# apollo4p register map
Vendor: Ambiq Micro; Series: Apollo; File version: 1.0
CPU: CM4 r1p0, little endian, MPU, FPU, I-cache, D-cache, VTOR, ITCM, DTCM, 3 interrupt priority bits, 0 interrupts
Registers are 32-bit, read-write, reset 0x0 unless marked. A register's access mark holds for its fields unless they carry their own. Offsets are from the block's base; [hi:lo] are bit positions; {n}, {i} and the like mark numbered series; 'fields as' and 'values as' point back to an identical list.

## GPIO (part 4 of 5) — General Purpose IO
Base 0x40010000
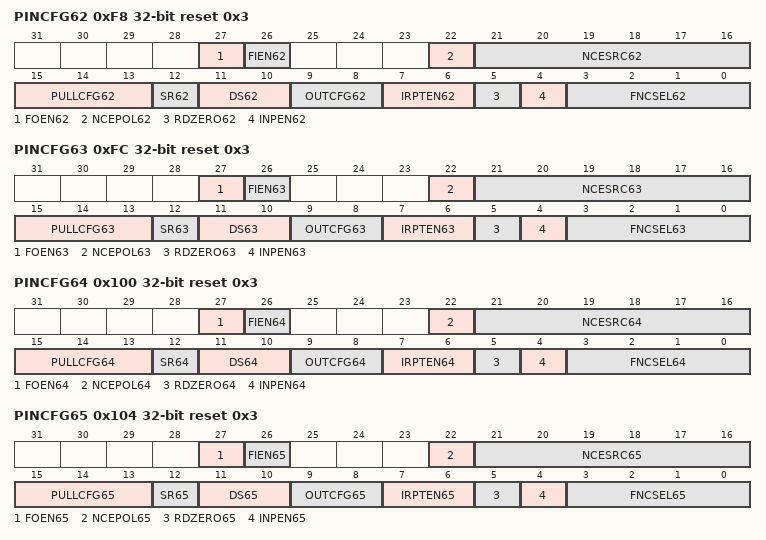
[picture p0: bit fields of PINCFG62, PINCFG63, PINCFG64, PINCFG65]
0xF8 PINCFG62 reset 0x3 — Controls the operation of GPIO pin 62.
  [27] FOEN62 — Force output enable active regardless of function selected. Otherwise the selected function will enable the output only when needed
  [26] FIEN62 — Force input enable active regardless of function selected. Otherwise the selected function will enable the input only when needed
  [22] NCEPOL62 — Polarity select for NCE for GPIO 62
    0=LOW (Polarity is active low); 1=HIGH (Polarity is active high)
  [21:16] NCESRC62 — IOMSTR/MSPI N Chip Select 62, DISP control signals DE, CSX, and CS. Polarity is determined by CE_POLARITY field
    {v}=IOM0CE{v} (IOM 0 NCE {v} module) (v=0..3); {v}=IOM1CE{v-4} (IOM 1 NCE {v-4} module) (v=4..7); {v}=IOM2CE{v-8} (IOM 2 NCE {v-8} module) (v=8..11); {v}=IOM3CE{v-12} (IOM 3 NCE {v-12} module) (v=12..15); {v}=IOM4CE{v-16} (IOM 4 NCE {v-16} module) (v=16..19); {v}=IOM5CE{v-20} (IOM 5 NCE {v-20} module) (v=20..23); {v}=IOM6CE{v-24} (IOM 6 NCE {v-24} module) (v=24..27); {v}=IOM7CE{v-28} (IOM 7 NCE {v-28} module) (v=28..31); 32=MSPI0CEN0 (MSPI 0 NCE 0 module); 33=MSPI0CEN1 (MSPI 0 NCE 1 module); 34=MSPI1CEN0 (MSPI 1 NCE 0 module); 35=MSPI1CEN1 (MSPI 1 NCE 1 module); 36=MSPI2CEN0 (MSPI 2 NCE 0 module); 37=MSPI2CEN1 (MSPI 2 NCE 1 module); 38=DC_DPI_DE (DC DPI DE module); 39=DISP_CONT_CSX (DISP CONT CSX module); 40=DC_SPI_CS_N (DC SPI CS_N module); 41=DC_QSPI_CS_N (DC QSPI CS_N module); 42=DC_RESX (DC module RESX)
  [15:13] PULLCFG62 — Pullup/Pulldown configuration for GPIO 62
    0=DIS (No pullup or pulldown selected); 1=PD50K (50K Pulldown selected); 2=PU15K (1.5K Pullup selected); 3=PU6K (6K Pullup selected); 4=PU12K (12K Pullup selected); 5=PU24K (24K Pullup selected); 6=PU50K (50K Pullup selected); 7=PU100K (100K Pullup selected)
  [12] SR62 — Configure the slew rate
  [11:10] DS62 — Drive strength selection for GPIO 62
    0=0P1X (0.1x output driver selected); 1=0P5X (0.5x output driver selected); 2=0P75X (0.75x output driver selected); 3=1P0X (1.0x output driver selected)
  [9:8] OUTCFG62 — Pin IO mode selection for GPIO pin 62
    0=DIS (Output Disabled); 1=PUSHPULL (Output configured in push pull mode. Will drive 0 and 1 values on pin.); 2=OD (Output configured in open drain mode. Will only drive pin low, tristate otherwise.); 3=TS (Output configured in Tristate-able push pull mode. Will drive 0, 1 of HiZ on pin.)
  [7:6] IRPTEN62 — Interrupt enable for GPIO 62
    0=DIS (Interrupts are disabled for this GPIO); 1=INTFALL (Interrupts are enabled for falling edge transition on this GPIO); 2=INTRISE (Interrupts are enabled for rising edge transitions on this GPIO); 3=INTANY (Interrupts are enabled for any edge transition on this GPIO)
  [5] RDZERO62 — Return 0 for read data on GPIO 62
  [4] INPEN62 — Input enable for GPIO 62
  [3:0] FNCSEL62 — Function select for GPIO pin 62
    0=M6SDAWIR3 (Serial I2C Master Data I/O (I2C Mode) Serial SPI Master Data I/O (SPI 3 wire mode) (IOM 6)); 1=M6MOSI (Serial SPI Master MOSI output (IOM 6)); 2=I2S1_DATA (Bidirectional I2S Data. Operates in output mode in master mode and input mode for slave mode. (I2S Master/Slave 2)); 3=GPIO (General purpose I/O); 4=UART0RX (UART receive input (UART 0)); 5=UART1RX (UART receive input (UART 1)); 6=CT62 (Timer/Counter input or output; Selection of direction is done via CTIMER register settings.); 7=NCE62 (IOMSTR/MSPI N Chip Select. Polarity is determined by CE_POLARITY field); 8=OBSBUS14 (Observation bus bit 14); 9=I2S1_SDOUT (I2S Data output (I2S Master/Slave 2)); 10=I3CM0_SDA (Serial I3C Master Data I/O (IOM 0)); 11=FPIO (Fast PIO)
0xFC PINCFG63 reset 0x3 — Controls the operation of GPIO pin 63.
  [27] FOEN63 — Force output enable active regardless of function selected. Otherwise the selected function will enable the output only when needed
  [26] FIEN63 — Force input enable active regardless of function selected. Otherwise the selected function will enable the input only when needed
  [22] NCEPOL63 — Polarity select for NCE for GPIO 63
    values as PINCFG62.NCEPOL62
  [21:16] NCESRC63 — IOMSTR/MSPI N Chip Select 63, DISP control signals DE, CSX, and CS. Polarity is determined by CE_POLARITY field
    values as PINCFG62.NCESRC62
  [15:13] PULLCFG63 — Pullup/Pulldown configuration for GPIO 63
    values as PINCFG62.PULLCFG62
  [12] SR63 — Configure the slew rate
  [11:10] DS63 — Drive strength selection for GPIO 63
    values as PINCFG62.DS62
  [9:8] OUTCFG63 — Pin IO mode selection for GPIO pin 63
    values as PINCFG62.OUTCFG62
  [7:6] IRPTEN63 — Interrupt enable for GPIO 63
    values as PINCFG62.IRPTEN62
  [5] RDZERO63 — Return 0 for read data on GPIO 63
  [4] INPEN63 — Input enable for GPIO 63
  [3:0] FNCSEL63 — Function select for GPIO pin 63
    0=M6MISO (Serial SPI MASTER MISO input (IOM 6)); 1=CLKOUT (Oscillator output clock); 2=I2S1_WS (Bidirectional I2S L/R clock. Operates in output mode in master mode and input mode for slave mode. (I2S Master/Slave 2)); 3=GPIO (General purpose I/O); 4=UART2RX (UART receive input (UART 2)); 5=UART3RX (UART receive input (UART 3)); 6=CT63 (Timer/Counter input or output; Selection of direction is done via CTIMER register settings.); 7=NCE63 (IOMSTR/MSPI N Chip Select. Polarity is determined by CE_POLARITY field); 8=OBSBUS15 (Observation bus bit 15); 9=DISP_TE (Display TE input); 11=FPIO (Fast PIO)
0x100 PINCFG64 reset 0x3 — Controls the operation of GPIO pin 64.
  [27] FOEN64 — Force output enable active regardless of function selected. Otherwise the selected function will enable the output only when needed
  [26] FIEN64 — Force input enable active regardless of function selected. Otherwise the selected function will enable the input only when needed
  [22] NCEPOL64 — Polarity select for NCE for GPIO 64
    values as PINCFG62.NCEPOL62
  [21:16] NCESRC64 — IOMSTR/MSPI N Chip Select 64, DISP control signals DE, CSX, and CS. Polarity is determined by CE_POLARITY field
    values as PINCFG62.NCESRC62
  [15:13] PULLCFG64 — Pullup/Pulldown configuration for GPIO 64
    values as PINCFG62.PULLCFG62
  [12] SR64 — Configure the slew rate
  [11:10] DS64 — Drive strength selection for GPIO 64
    values as PINCFG62.DS62
  [9:8] OUTCFG64 — Pin IO mode selection for GPIO pin 64
    values as PINCFG62.OUTCFG62
  [7:6] IRPTEN64 — Interrupt enable for GPIO 64
    values as PINCFG62.IRPTEN62
  [5] RDZERO64 — Return 0 for read data on GPIO 64
  [4] INPEN64 — Input enable for GPIO 64
  [3:0] FNCSEL64 — Function select for GPIO pin 64
    0=MSPI0_0 (MSPI Master 0 Interface Signal); 1=32KHzXT (32kHZ from analog); 2=SWO (Serial Wire Output); 3=GPIO (General purpose I/O); 4=UART0RTS (UART Request to Send (RTS) (UART 0)); 5=DISP_D0 (Display Data 0); 6=CT64 (Timer/Counter input or output; Selection of direction is done via CTIMER register settings.); 7=NCE64 (IOMSTR/MSPI N Chip Select. Polarity is determined by CE_POLARITY field); 8=OBSBUS0 (Observation bus bit 0); 9=I2S1_SDIN (I2S Data input (I2S Master/Slave 2)); 11=FPIO (Fast PIO)
0x104 PINCFG65 reset 0x3 — Controls the operation of GPIO pin 65.
  [27] FOEN65 — Force output enable active regardless of function selected. Otherwise the selected function will enable the output only when needed
  [26] FIEN65 — Force input enable active regardless of function selected. Otherwise the selected function will enable the input only when needed
  [22] NCEPOL65 — Polarity select for NCE for GPIO 65
    values as PINCFG62.NCEPOL62
  [21:16] NCESRC65 — IOMSTR/MSPI N Chip Select 65, DISP control signals DE, CSX, and CS. Polarity is determined by CE_POLARITY field
    values as PINCFG62.NCESRC62
  [15:13] PULLCFG65 — Pullup/Pulldown configuration for GPIO 65
    values as PINCFG62.PULLCFG62
  [12] SR65 — Configure the slew rate
  [11:10] DS65 — Drive strength selection for GPIO 65
    values as PINCFG62.DS62
  [9:8] OUTCFG65 — Pin IO mode selection for GPIO pin 65
    values as PINCFG62.OUTCFG62
  [7:6] IRPTEN65 — Interrupt enable for GPIO 65
    values as PINCFG62.IRPTEN62
  [5] RDZERO65 — Return 0 for read data on GPIO 65
  [4] INPEN65 — Input enable for GPIO 65
  [3:0] FNCSEL65 — Function select for GPIO pin 65
    0=MSPI0_1 (MSPI Master 0 Interface Signal); 1=32KHzXT (32kHZ from analog); 2=SWO (Serial Wire Output); 3=GPIO (General purpose I/O); 4=UART0CTS (UART Clear to Send (CTS) (UART 0)); 5=DISP_D1 (Display Data 1); 6=CT65 (Timer/Counter input or output; Selection of direction is done via CTIMER register settings.); 7=NCE65 (IOMSTR/MSPI N Chip Select. Polarity is determined by CE_POLARITY field); 8=OBSBUS1 (Observation bus bit 1); 11=FPIO (Fast PIO)
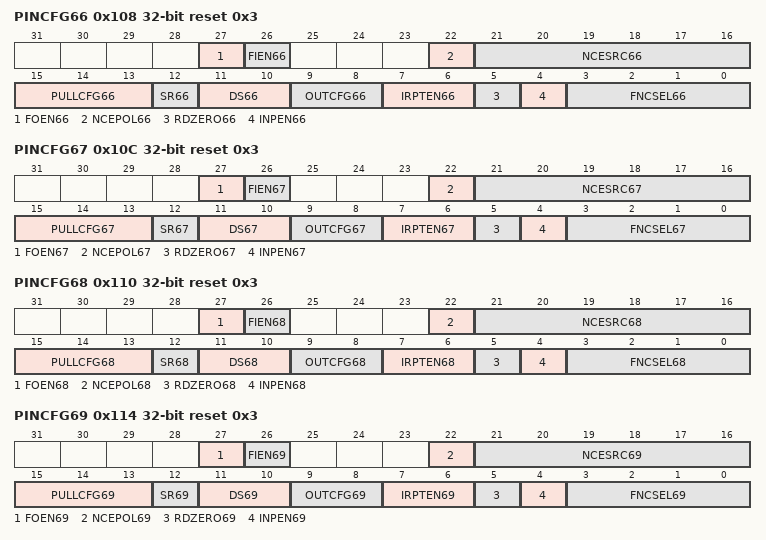
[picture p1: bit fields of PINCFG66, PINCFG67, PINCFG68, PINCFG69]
0x108 PINCFG66 reset 0x3 — Controls the operation of GPIO pin 66.
  [27] FOEN66 — Force output enable active regardless of function selected. Otherwise the selected function will enable the output only when needed
  [26] FIEN66 — Force input enable active regardless of function selected. Otherwise the selected function will enable the input only when needed
  [22] NCEPOL66 — Polarity select for NCE for GPIO 66
    values as PINCFG62.NCEPOL62
  [21:16] NCESRC66 — IOMSTR/MSPI N Chip Select 66, DISP control signals DE, CSX, and CS. Polarity is determined by CE_POLARITY field
    values as PINCFG62.NCESRC62
  [15:13] PULLCFG66 — Pullup/Pulldown configuration for GPIO 66
    values as PINCFG62.PULLCFG62
  [12] SR66 — Configure the slew rate
  [11:10] DS66 — Drive strength selection for GPIO 66
    values as PINCFG62.DS62
  [9:8] OUTCFG66 — Pin IO mode selection for GPIO pin 66
    values as PINCFG62.OUTCFG62
  [7:6] IRPTEN66 — Interrupt enable for GPIO 66
    values as PINCFG62.IRPTEN62
  [5] RDZERO66 — Return 0 for read data on GPIO 66
  [4] INPEN66 — Input enable for GPIO 66
  [3:0] FNCSEL66 — Function select for GPIO pin 66
    0=MSPI0_2 (MSPI Master 0 Interface Signal); 1=CLKOUT (Oscillator output clock); 2=SWO (Serial Wire Output); 3=GPIO (General purpose I/O); 4=UART0TX (UART transmit output (UART 0)); 5=DISP_D2 (Display Data 2); 6=CT66 (Timer/Counter input or output; Selection of direction is done via CTIMER register settings.); 7=NCE66 (IOMSTR/MSPI N Chip Select. Polarity is determined by CE_POLARITY field); 8=OBSBUS2 (Observation bus bit 2); 11=FPIO (Fast PIO)
0x10C PINCFG67 reset 0x3 — Controls the operation of GPIO pin 67.
  [27] FOEN67 — Force output enable active regardless of function selected. Otherwise the selected function will enable the output only when needed
  [26] FIEN67 — Force input enable active regardless of function selected. Otherwise the selected function will enable the input only when needed
  [22] NCEPOL67 — Polarity select for NCE for GPIO 67
    values as PINCFG62.NCEPOL62
  [21:16] NCESRC67 — IOMSTR/MSPI N Chip Select 67, DISP control signals DE, CSX, and CS. Polarity is determined by CE_POLARITY field
    values as PINCFG62.NCESRC62
  [15:13] PULLCFG67 — Pullup/Pulldown configuration for GPIO 67
    values as PINCFG62.PULLCFG62
  [12] SR67 — Configure the slew rate
  [11:10] DS67 — Drive strength selection for GPIO 67
    values as PINCFG62.DS62
  [9:8] OUTCFG67 — Pin IO mode selection for GPIO pin 67
    values as PINCFG62.OUTCFG62
  [7:6] IRPTEN67 — Interrupt enable for GPIO 67
    values as PINCFG62.IRPTEN62
  [5] RDZERO67 — Return 0 for read data on GPIO 67
  [4] INPEN67 — Input enable for GPIO 67
  [3:0] FNCSEL67 — Function select for GPIO pin 67
    0=MSPI0_3 (MSPI Master 0 Interface Signal); 1=CLKOUT (Oscillator output clock); 2=SWO (Serial Wire Output); 3=GPIO (General purpose I/O); 4=UART2TX (UART transmit output (UART 2)); 5=DISP_D3 (Display Data 3); 6=CT67 (Timer/Counter input or output; Selection of direction is done via CTIMER register settings.); 7=NCE67 (IOMSTR/MSPI N Chip Select. Polarity is determined by CE_POLARITY field); 8=OBSBUS3 (Observation bus bit 3); 11=FPIO (Fast PIO)
0x110 PINCFG68 reset 0x3 — Controls the operation of GPIO pin 68.
  [27] FOEN68 — Force output enable active regardless of function selected. Otherwise the selected function will enable the output only when needed
  [26] FIEN68 — Force input enable active regardless of function selected. Otherwise the selected function will enable the input only when needed
  [22] NCEPOL68 — Polarity select for NCE for GPIO 68
    values as PINCFG62.NCEPOL62
  [21:16] NCESRC68 — IOMSTR/MSPI N Chip Select 68, DISP control signals DE, CSX, and CS. Polarity is determined by CE_POLARITY field
    values as PINCFG62.NCESRC62
  [15:13] PULLCFG68 — Pullup/Pulldown configuration for GPIO 68
    values as PINCFG62.PULLCFG62
  [12] SR68 — Configure the slew rate
  [11:10] DS68 — Drive strength selection for GPIO 68
    values as PINCFG62.DS62
  [9:8] OUTCFG68 — Pin IO mode selection for GPIO pin 68
    values as PINCFG62.OUTCFG62
  [7:6] IRPTEN68 — Interrupt enable for GPIO 68
    values as PINCFG62.IRPTEN62
  [5] RDZERO68 — Return 0 for read data on GPIO 68
  [4] INPEN68 — Input enable for GPIO 68
  [3:0] FNCSEL68 — Function select for GPIO pin 68
    0=MSPI0_4 (MSPI Master 0 Interface Signal); 1=SWO (Serial Wire Output); 3=GPIO (General purpose I/O); 4=UART0RX (UART receive input (UART 0)); 5=DISP_D4 (Display Data 4); 6=CT68 (Timer/Counter input or output; Selection of direction is done via CTIMER register settings.); 7=NCE68 (IOMSTR/MSPI N Chip Select. Polarity is determined by CE_POLARITY field); 8=OBSBUS4 (Observation bus bit 4); 11=FPIO (Fast PIO)
0x114 PINCFG69 reset 0x3 — Controls the operation of GPIO pin 69.
  [27] FOEN69 — Force output enable active regardless of function selected. Otherwise the selected function will enable the output only when needed
  [26] FIEN69 — Force input enable active regardless of function selected. Otherwise the selected function will enable the input only when needed
  [22] NCEPOL69 — Polarity select for NCE for GPIO 69
    values as PINCFG62.NCEPOL62
  [21:16] NCESRC69 — IOMSTR/MSPI N Chip Select 69, DISP control signals DE, CSX, and CS. Polarity is determined by CE_POLARITY field
    values as PINCFG62.NCESRC62
  [15:13] PULLCFG69 — Pullup/Pulldown configuration for GPIO 69
    values as PINCFG62.PULLCFG62
  [12] SR69 — Configure the slew rate
  [11:10] DS69 — Drive strength selection for GPIO 69
    values as PINCFG62.DS62
  [9:8] OUTCFG69 — Pin IO mode selection for GPIO pin 69
    values as PINCFG62.OUTCFG62
  [7:6] IRPTEN69 — Interrupt enable for GPIO 69
    values as PINCFG62.IRPTEN62
  [5] RDZERO69 — Return 0 for read data on GPIO 69
  [4] INPEN69 — Input enable for GPIO 69
  [3:0] FNCSEL69 — Function select for GPIO pin 69
    0=MSPI0_5 (MSPI Master 0 Interface Signal); 1=32KHzXT (32kHZ from analog); 2=SWO (Serial Wire Output); 3=GPIO (General purpose I/O); 4=UART2RX (UART receive input (UART 2)); 5=DISP_D5 (Display Data 5); 6=CT69 (Timer/Counter input or output; Selection of direction is done via CTIMER register settings.); 7=NCE69 (IOMSTR/MSPI N Chip Select. Polarity is determined by CE_POLARITY field); 8=OBSBUS5 (Observation bus bit 5); 11=FPIO (Fast PIO)
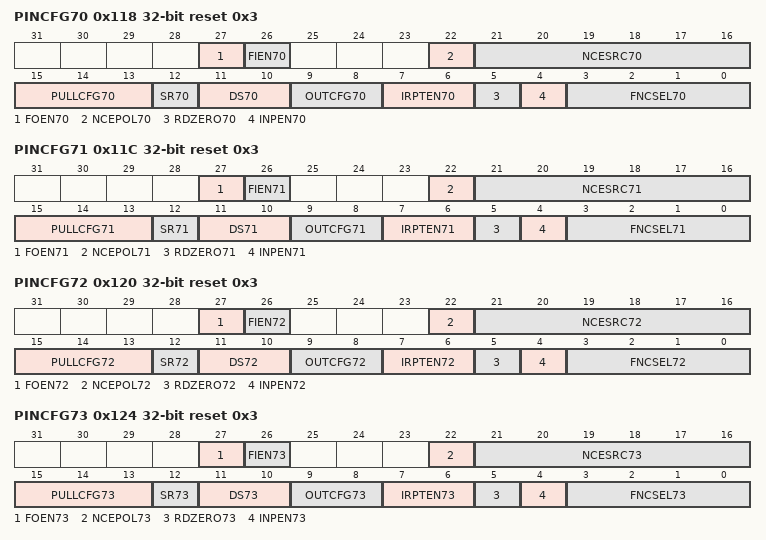
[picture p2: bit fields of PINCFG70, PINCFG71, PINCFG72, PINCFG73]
0x118 PINCFG70 reset 0x3 — Controls the operation of GPIO pin 70.
  [27] FOEN70 — Force output enable active regardless of function selected. Otherwise the selected function will enable the output only when needed
  [26] FIEN70 — Force input enable active regardless of function selected. Otherwise the selected function will enable the input only when needed
  [22] NCEPOL70 — Polarity select for NCE for GPIO 70
    values as PINCFG62.NCEPOL62
  [21:16] NCESRC70 — IOMSTR/MSPI N Chip Select 70, DISP control signals DE, CSX, and CS. Polarity is determined by CE_POLARITY field
    values as PINCFG62.NCESRC62
  [15:13] PULLCFG70 — Pullup/Pulldown configuration for GPIO 70
    values as PINCFG62.PULLCFG62
  [12] SR70 — Configure the slew rate
  [11:10] DS70 — Drive strength selection for GPIO 70
    values as PINCFG62.DS62
  [9:8] OUTCFG70 — Pin IO mode selection for GPIO pin 70
    values as PINCFG62.OUTCFG62
  [7:6] IRPTEN70 — Interrupt enable for GPIO 70
    values as PINCFG62.IRPTEN62
  [5] RDZERO70 — Return 0 for read data on GPIO 70
  [4] INPEN70 — Input enable for GPIO 70
  [3:0] FNCSEL70 — Function select for GPIO pin 70
    0=MSPI0_6 (MSPI Master 0 Interface Signal); 1=32KHzXT (32kHZ from analog); 2=SWTRACE0 (Serial Wire Debug Trace Output 0); 3=GPIO (General purpose I/O); 4=UART0RTS (UART Request to Send (RTS) (UART 0)); 5=DISP_D6 (Display Data 6); 6=CT70 (Timer/Counter input or output; Selection of direction is done via CTIMER register settings.); 7=NCE70 (IOMSTR/MSPI N Chip Select. Polarity is determined by CE_POLARITY field); 8=OBSBUS6 (Observation bus bit 6); 11=FPIO (Fast PIO)
0x11C PINCFG71 reset 0x3 — Controls the operation of GPIO pin 71.
  [27] FOEN71 — Force output enable active regardless of function selected. Otherwise the selected function will enable the output only when needed
  [26] FIEN71 — Force input enable active regardless of function selected. Otherwise the selected function will enable the input only when needed
  [22] NCEPOL71 — Polarity select for NCE for GPIO 71
    values as PINCFG62.NCEPOL62
  [21:16] NCESRC71 — IOMSTR/MSPI N Chip Select 71, DISP control signals DE, CSX, and CS. Polarity is determined by CE_POLARITY field
    values as PINCFG62.NCESRC62
  [15:13] PULLCFG71 — Pullup/Pulldown configuration for GPIO 71
    values as PINCFG62.PULLCFG62
  [12] SR71 — Configure the slew rate
  [11:10] DS71 — Drive strength selection for GPIO 71
    values as PINCFG62.DS62
  [9:8] OUTCFG71 — Pin IO mode selection for GPIO pin 71
    values as PINCFG62.OUTCFG62
  [7:6] IRPTEN71 — Interrupt enable for GPIO 71
    values as PINCFG62.IRPTEN62
  [5] RDZERO71 — Return 0 for read data on GPIO 71
  [4] INPEN71 — Input enable for GPIO 71
  [3:0] FNCSEL71 — Function select for GPIO pin 71
    0=MSPI0_7 (MSPI Master 0 Interface Signal); 1=CLKOUT (Oscillator output clock); 2=SWTRACE1 (Serial Wire Debug Trace Output 1); 3=GPIO (General purpose I/O); 4=UART0CTS (UART Clear to Send (CTS) (UART 0)); 5=DISP_D7 (Display Data 7); 6=CT71 (Timer/Counter input or output; Selection of direction is done via CTIMER register settings.); 7=NCE71 (IOMSTR/MSPI N Chip Select. Polarity is determined by CE_POLARITY field); 8=OBSBUS7 (Observation bus bit 7); 11=FPIO (Fast PIO)
0x120 PINCFG72 reset 0x3 — Controls the operation of GPIO pin 72.
  [27] FOEN72 — Force output enable active regardless of function selected. Otherwise the selected function will enable the output only when needed
  [26] FIEN72 — Force input enable active regardless of function selected. Otherwise the selected function will enable the input only when needed
  [22] NCEPOL72 — Polarity select for NCE for GPIO 72
    values as PINCFG62.NCEPOL62
  [21:16] NCESRC72 — IOMSTR/MSPI N Chip Select 72, DISP control signals DE, CSX, and CS. Polarity is determined by CE_POLARITY field
    values as PINCFG62.NCESRC62
  [15:13] PULLCFG72 — Pullup/Pulldown configuration for GPIO 72
    values as PINCFG62.PULLCFG62
  [12] SR72 — Configure the slew rate
  [11:10] DS72 — Drive strength selection for GPIO 72
    values as PINCFG62.DS62
  [9:8] OUTCFG72 — Pin IO mode selection for GPIO pin 72
    values as PINCFG62.OUTCFG62
  [7:6] IRPTEN72 — Interrupt enable for GPIO 72
    values as PINCFG62.IRPTEN62
  [5] RDZERO72 — Return 0 for read data on GPIO 72
  [4] INPEN72 — Input enable for GPIO 72
  [3:0] FNCSEL72 — Function select for GPIO pin 72
    0=MSPI0_8 (MSPI Master 0 Interface Signal); 1=CLKOUT (Oscillator output clock); 2=SWTRACE2 (Serial Wire Debug Trace Output 2); 3=GPIO (General purpose I/O); 4=UART0TX (UART transmit output (UART 0)); 5=DISP_D8 (Display Data 8); 6=CT72 (Timer/Counter input or output; Selection of direction is done via CTIMER register settings.); 7=NCE72 (IOMSTR/MSPI N Chip Select. Polarity is determined by CE_POLARITY field); 8=OBSBUS8 (Observation bus bit 8); 9=VCMPO (Output of the voltage comparator signal); 11=FPIO (Fast PIO)
0x124 PINCFG73 reset 0x3 — Controls the operation of GPIO pin 73.
  [27] FOEN73 — Force output enable active regardless of function selected. Otherwise the selected function will enable the output only when needed
  [26] FIEN73 — Force input enable active regardless of function selected. Otherwise the selected function will enable the input only when needed
  [22] NCEPOL73 — Polarity select for NCE for GPIO 73
    values as PINCFG62.NCEPOL62
  [21:16] NCESRC73 — IOMSTR/MSPI N Chip Select 73, DISP control signals DE, CSX, and CS. Polarity is determined by CE_POLARITY field
    values as PINCFG62.NCESRC62
  [15:13] PULLCFG73 — Pullup/Pulldown configuration for GPIO 73
    values as PINCFG62.PULLCFG62
  [12] SR73 — Configure the slew rate
  [11:10] DS73 — Drive strength selection for GPIO 73
    values as PINCFG62.DS62
  [9:8] OUTCFG73 — Pin IO mode selection for GPIO pin 73
    values as PINCFG62.OUTCFG62
  [7:6] IRPTEN73 — Interrupt enable for GPIO 73
    values as PINCFG62.IRPTEN62
  [5] RDZERO73 — Return 0 for read data on GPIO 73
  [4] INPEN73 — Input enable for GPIO 73
  [3:0] FNCSEL73 — Function select for GPIO pin 73
    0=MSPI0_9 (MSPI Master 0 Interface Signal); 2=SWTRACE3 (Serial Wire Debug Trace Output 3); 3=GPIO (General purpose I/O); 4=UART2TX (UART transmit output (UART 2)); 5=DISP_D9 (Display Data 9); 6=CT73 (Timer/Counter input or output; Selection of direction is done via CTIMER register settings.); 7=NCE73 (IOMSTR/MSPI N Chip Select. Polarity is determined by CE_POLARITY field); 8=OBSBUS9 (Observation bus bit 9); 11=FPIO (Fast PIO)
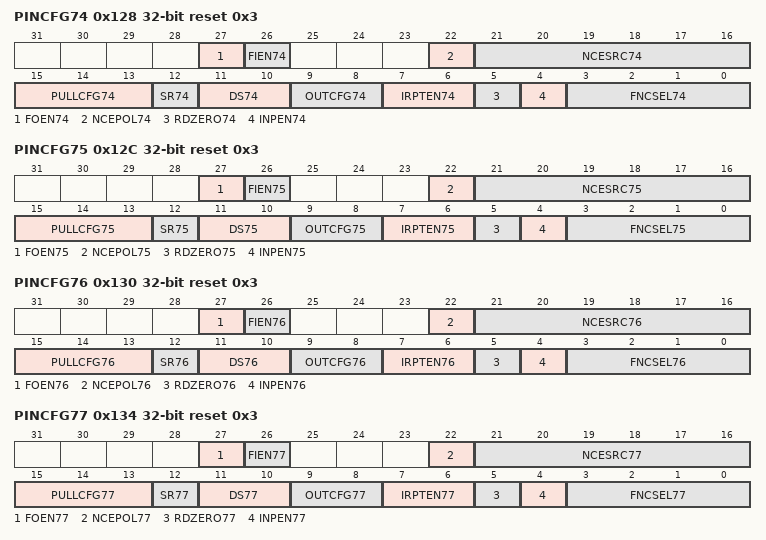
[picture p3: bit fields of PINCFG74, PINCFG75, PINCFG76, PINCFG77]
0x128 PINCFG74 reset 0x3 — Controls the operation of GPIO pin 74.
  [27] FOEN74 — Force output enable active regardless of function selected. Otherwise the selected function will enable the output only when needed
  [26] FIEN74 — Force input enable active regardless of function selected. Otherwise the selected function will enable the input only when needed
  [22] NCEPOL74 — Polarity select for NCE for GPIO 74
    values as PINCFG62.NCEPOL62
  [21:16] NCESRC74 — IOMSTR/MSPI N Chip Select 74, DISP control signals DE, CSX, and CS. Polarity is determined by CE_POLARITY field
    values as PINCFG62.NCESRC62
  [15:13] PULLCFG74 — Pullup/Pulldown configuration for GPIO 74
    values as PINCFG62.PULLCFG62
  [12] SR74 — Configure the slew rate
  [11:10] DS74 — Drive strength selection for GPIO 74
    values as PINCFG62.DS62
  [9:8] OUTCFG74 — Pin IO mode selection for GPIO pin 74
    values as PINCFG62.OUTCFG62
  [7:6] IRPTEN74 — Interrupt enable for GPIO 74
    values as PINCFG62.IRPTEN62
  [5] RDZERO74 — Return 0 for read data on GPIO 74
  [4] INPEN74 — Input enable for GPIO 74
  [3:0] FNCSEL74 — Function select for GPIO pin 74
    0=MSPI2_0 (MSPI Master 2 Interface Signal); 1=DISP_QSPI_D0_OUT (Display SPI Data0); 2=DISP_QSPI_D0 (Display SPI Data0); 3=GPIO (General purpose I/O); 4=UART0RX (UART receive input (UART 0)); 5=DISP_D10 (Display Data 10); 6=CT74 (Timer/Counter input or output; Selection of direction is done via CTIMER register settings.); 7=NCE74 (IOMSTR/MSPI N Chip Select. Polarity is determined by CE_POLARITY field); 8=OBSBUS10 (Observation bus bit 10); 9=DISP_SPI_SD (Display SPI Data Out); 10=DISP_SPI_SDO (Display SPI Data Out); 11=FPIO (Fast PIO)
0x12C PINCFG75 reset 0x3 — Controls the operation of GPIO pin 75.
  [27] FOEN75 — Force output enable active regardless of function selected. Otherwise the selected function will enable the output only when needed
  [26] FIEN75 — Force input enable active regardless of function selected. Otherwise the selected function will enable the input only when needed
  [22] NCEPOL75 — Polarity select for NCE for GPIO 75
    values as PINCFG62.NCEPOL62
  [21:16] NCESRC75 — IOMSTR/MSPI N Chip Select 75, DISP control signals DE, CSX, and CS. Polarity is determined by CE_POLARITY field
    values as PINCFG62.NCESRC62
  [15:13] PULLCFG75 — Pullup/Pulldown configuration for GPIO 75
    values as PINCFG62.PULLCFG62
  [12] SR75 — Configure the slew rate
  [11:10] DS75 — Drive strength selection for GPIO 75
    values as PINCFG62.DS62
  [9:8] OUTCFG75 — Pin IO mode selection for GPIO pin 75
    values as PINCFG62.OUTCFG62
  [7:6] IRPTEN75 — Interrupt enable for GPIO 75
    values as PINCFG62.IRPTEN62
  [5] RDZERO75 — Return 0 for read data on GPIO 75
  [4] INPEN75 — Input enable for GPIO 75
  [3:0] FNCSEL75 — Function select for GPIO pin 75
    0=MSPI2_1 (MSPI Master 2 Interface Signal); 1=32KHzXT (32kHZ from analog); 2=DISP_QSPI_D1 (Display SPI Data1); 3=GPIO (General purpose I/O); 4=UART2RX (UART receive input (UART 2)); 5=DISP_D11 (Display Data 11); 6=CT75 (Timer/Counter input or output; Selection of direction is done via CTIMER register settings.); 7=NCE75 (IOMSTR/MSPI N Chip Select. Polarity is determined by CE_POLARITY field); 8=OBSBUS11 (Observation bus bit 11); 9=DISP_SPI_DCX (Display SPI DCx); 11=FPIO (Fast PIO)
0x130 PINCFG76 reset 0x3 — Controls the operation of GPIO pin 76.
  [27] FOEN76 — Force output enable active regardless of function selected. Otherwise the selected function will enable the output only when needed
  [26] FIEN76 — Force input enable active regardless of function selected. Otherwise the selected function will enable the input only when needed
  [22] NCEPOL76 — Polarity select for NCE for GPIO 76
    values as PINCFG62.NCEPOL62
  [21:16] NCESRC76 — IOMSTR/MSPI N Chip Select 76, DISP control signals DE, CSX, and CS. Polarity is determined by CE_POLARITY field
    values as PINCFG62.NCESRC62
  [15:13] PULLCFG76 — Pullup/Pulldown configuration for GPIO 76
    values as PINCFG62.PULLCFG62
  [12] SR76 — Configure the slew rate
  [11:10] DS76 — Drive strength selection for GPIO 76
    values as PINCFG62.DS62
  [9:8] OUTCFG76 — Pin IO mode selection for GPIO pin 76
    values as PINCFG62.OUTCFG62
  [7:6] IRPTEN76 — Interrupt enable for GPIO 76
    values as PINCFG62.IRPTEN62
  [5] RDZERO76 — Return 0 for read data on GPIO 76
  [4] INPEN76 — Input enable for GPIO 76
  [3:0] FNCSEL76 — Function select for GPIO pin 76
    0=MSPI2_2 (MSPI Master 2 Interface Signal); 1=32KHzXT (32kHZ from analog); 2=DISP_QSPI_D2 (Display SPI Data2); 3=GPIO (General purpose I/O); 4=UART0RTS (UART Request to Send (RTS) (UART 0)); 5=DISP_D12 (Display Data 12); 6=CT76 (Timer/Counter input or output; Selection of direction is done via CTIMER register settings.); 7=NCE76 (IOMSTR/MSPI N Chip Select. Polarity is determined by CE_POLARITY field); 8=OBSBUS12 (Observation bus bit 12); 11=FPIO (Fast PIO)
0x134 PINCFG77 reset 0x3 — Controls the operation of GPIO pin 77.
  [27] FOEN77 — Force output enable active regardless of function selected. Otherwise the selected function will enable the output only when needed
  [26] FIEN77 — Force input enable active regardless of function selected. Otherwise the selected function will enable the input only when needed
  [22] NCEPOL77 — Polarity select for NCE for GPIO 77
    values as PINCFG62.NCEPOL62
  [21:16] NCESRC77 — IOMSTR/MSPI N Chip Select 77, DISP control signals DE, CSX, and CS. Polarity is determined by CE_POLARITY field
    values as PINCFG62.NCESRC62
  [15:13] PULLCFG77 — Pullup/Pulldown configuration for GPIO 77
    values as PINCFG62.PULLCFG62
  [12] SR77 — Configure the slew rate
  [11:10] DS77 — Drive strength selection for GPIO 77
    values as PINCFG62.DS62
  [9:8] OUTCFG77 — Pin IO mode selection for GPIO pin 77
    values as PINCFG62.OUTCFG62
  [7:6] IRPTEN77 — Interrupt enable for GPIO 77
    values as PINCFG62.IRPTEN62
  [5] RDZERO77 — Return 0 for read data on GPIO 77
  [4] INPEN77 — Input enable for GPIO 77
  [3:0] FNCSEL77 — Function select for GPIO pin 77
    0=MSPI2_3 (MSPI Master 2 Interface Signal); 2=DISP_QSPI_D3 (Display SPI Data3); 3=GPIO (General purpose I/O); 4=UART0CTS (UART Clear to Send (CTS) (UART 0)); 5=DISP_D13 (Display Data 13); 6=CT77 (Timer/Counter input or output; Selection of direction is done via CTIMER register settings.); 7=NCE77 (IOMSTR/MSPI N Chip Select. Polarity is determined by CE_POLARITY field); 8=OBSBUS13 (Observation bus bit 13); 11=FPIO (Fast PIO)
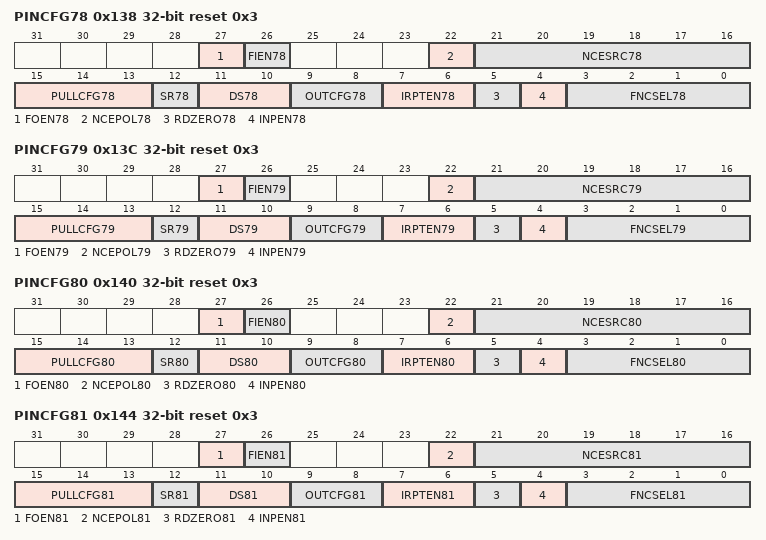
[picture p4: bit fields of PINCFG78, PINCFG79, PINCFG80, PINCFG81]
0x138 PINCFG78 reset 0x3 — Controls the operation of GPIO pin 78.
  [27] FOEN78 — Force output enable active regardless of function selected. Otherwise the selected function will enable the output only when needed
  [26] FIEN78 — Force input enable active regardless of function selected. Otherwise the selected function will enable the input only when needed
  [22] NCEPOL78 — Polarity select for NCE for GPIO 78
    values as PINCFG62.NCEPOL62
  [21:16] NCESRC78 — IOMSTR/MSPI N Chip Select 78, DISP control signals DE, CSX, and CS. Polarity is determined by CE_POLARITY field
    values as PINCFG62.NCESRC62
  [15:13] PULLCFG78 — Pullup/Pulldown configuration for GPIO 78
    values as PINCFG62.PULLCFG62
  [12] SR78 — Configure the slew rate
  [11:10] DS78 — Drive strength selection for GPIO 78
    values as PINCFG62.DS62
  [9:8] OUTCFG78 — Pin IO mode selection for GPIO pin 78
    values as PINCFG62.OUTCFG62
  [7:6] IRPTEN78 — Interrupt enable for GPIO 78
    values as PINCFG62.IRPTEN62
  [5] RDZERO78 — Return 0 for read data on GPIO 78
  [4] INPEN78 — Input enable for GPIO 78
  [3:0] FNCSEL78 — Function select for GPIO pin 78
    0=MSPI2_4 (MSPI Master 2 Interface Signal); 2=DISP_QSPI_SCK (Display SPI CLK); 3=GPIO (General purpose I/O); 4=UART0TX (UART transmit output (UART 0)); 5=DISP_D14 (Display Data 14); 6=CT78 (Timer/Counter input or output; Selection of direction is done via CTIMER register settings.); 7=NCE78 (IOMSTR/MSPI N Chip Select. Polarity is determined by CE_POLARITY field); 8=OBSBUS14 (Observation bus bit 14); 9=DISP_SPI_SCK (Display SPI Clock); 11=FPIO (Fast PIO)
0x13C PINCFG79 reset 0x3 — Controls the operation of GPIO pin 79.
  [27] FOEN79 — Force output enable active regardless of function selected. Otherwise the selected function will enable the output only when needed
  [26] FIEN79 — Force input enable active regardless of function selected. Otherwise the selected function will enable the input only when needed
  [22] NCEPOL79 — Polarity select for NCE for GPIO 79
    values as PINCFG62.NCEPOL62
  [21:16] NCESRC79 — IOMSTR/MSPI N Chip Select 79, DISP control signals DE, CSX, and CS. Polarity is determined by CE_POLARITY field
    values as PINCFG62.NCESRC62
  [15:13] PULLCFG79 — Pullup/Pulldown configuration for GPIO 79
    values as PINCFG62.PULLCFG62
  [12] SR79 — Configure the slew rate
  [11:10] DS79 — Drive strength selection for GPIO 79
    values as PINCFG62.DS62
  [9:8] OUTCFG79 — Pin IO mode selection for GPIO pin 79
    values as PINCFG62.OUTCFG62
  [7:6] IRPTEN79 — Interrupt enable for GPIO 79
    values as PINCFG62.IRPTEN62
  [5] RDZERO79 — Return 0 for read data on GPIO 79
  [4] INPEN79 — Input enable for GPIO 79
  [3:0] FNCSEL79 — Function select for GPIO pin 79
    0=MSPI2_5 (MSPI Master 2 Interface Signal); 2=SDIF_DAT4 (SD/SDIO/MMC Data4 pin); 3=GPIO (General purpose I/O); 4=SWO (Serial Wire Output); 5=DISP_VS (Display RGB VSYNC); 6=CT79 (Timer/Counter input or output; Selection of direction is done via CTIMER register settings.); 7=NCE79 (IOMSTR/MSPI N Chip Select. Polarity is determined by CE_POLARITY field); 8=OBSBUS15 (Observation bus bit 15); 9=DISP_SPI_SDI (Display SPI Data IN); 11=FPIO (Fast PIO)
0x140 PINCFG80 reset 0x3 — Controls the operation of GPIO pin 80.
  [27] FOEN80 — Force output enable active regardless of function selected. Otherwise the selected function will enable the output only when needed
  [26] FIEN80 — Force input enable active regardless of function selected. Otherwise the selected function will enable the input only when needed
  [22] NCEPOL80 — Polarity select for NCE for GPIO 80
    values as PINCFG62.NCEPOL62
  [21:16] NCESRC80 — IOMSTR/MSPI N Chip Select 80, DISP control signals DE, CSX, and CS. Polarity is determined by CE_POLARITY field
    values as PINCFG62.NCESRC62
  [15:13] PULLCFG80 — Pullup/Pulldown configuration for GPIO 80
    values as PINCFG62.PULLCFG62
  [12] SR80 — Configure the slew rate
  [11:10] DS80 — Drive strength selection for GPIO 80
    values as PINCFG62.DS62
  [9:8] OUTCFG80 — Pin IO mode selection for GPIO pin 80
    values as PINCFG62.OUTCFG62
  [7:6] IRPTEN80 — Interrupt enable for GPIO 80
    values as PINCFG62.IRPTEN62
  [5] RDZERO80 — Return 0 for read data on GPIO 80
  [4] INPEN80 — Input enable for GPIO 80
  [3:0] FNCSEL80 — Function select for GPIO pin 80
    0=MSPI2_6 (MSPI Master 2 Interface Signal); 1=CLKOUT (Oscillator output clock); 2=SDIF_DAT5 (SD/SDIO/MMC Data5 pin); 3=GPIO (General purpose I/O); 4=SWTRACE0 (Serial Wire Debug Trace Output 0); 5=DISP_HS (Display RGB HSYNC); 6=CT80 (Timer/Counter input or output; Selection of direction is done via CTIMER register settings.); 7=NCE80 (IOMSTR/MSPI N Chip Select. Polarity is determined by CE_POLARITY field); 8=OBSBUS0 (Observation bus bit 0); 11=FPIO (Fast PIO)
0x144 PINCFG81 reset 0x3 — Controls the operation of GPIO pin 81.
  [27] FOEN81 — Force output enable active regardless of function selected. Otherwise the selected function will enable the output only when needed
  [26] FIEN81 — Force input enable active regardless of function selected. Otherwise the selected function will enable the input only when needed
  [22] NCEPOL81 — Polarity select for NCE for GPIO 81
    values as PINCFG62.NCEPOL62
  [21:16] NCESRC81 — IOMSTR/MSPI N Chip Select 81, DISP control signals DE, CSX, and CS. Polarity is determined by CE_POLARITY field
    values as PINCFG62.NCESRC62
  [15:13] PULLCFG81 — Pullup/Pulldown configuration for GPIO 81
    values as PINCFG62.PULLCFG62
  [12] SR81 — Configure the slew rate
  [11:10] DS81 — Drive strength selection for GPIO 81
    values as PINCFG62.DS62
  [9:8] OUTCFG81 — Pin IO mode selection for GPIO pin 81
    values as PINCFG62.OUTCFG62
  [7:6] IRPTEN81 — Interrupt enable for GPIO 81
    values as PINCFG62.IRPTEN62
  [5] RDZERO81 — Return 0 for read data on GPIO 81
  [4] INPEN81 — Input enable for GPIO 81
  [3:0] FNCSEL81 — Function select for GPIO pin 81
    0=MSPI2_7 (MSPI Master 2 Interface Signal); 1=CLKOUT (Oscillator output clock); 2=SDIF_DAT6 (SD/SDIO/MMC Data6 pin); 3=GPIO (General purpose I/O); 4=SWTRACE1 (Serial Wire Debug Trace Output 1); 5=DISP_DE (Display RGB Data Enable); 6=CT81 (Timer/Counter input or output; Selection of direction is done via CTIMER register settings.); 7=NCE81 (IOMSTR/MSPI N Chip Select. Polarity is determined by CE_POLARITY field); 8=OBSBUS1 (Observation bus bit 1); 11=FPIO (Fast PIO)
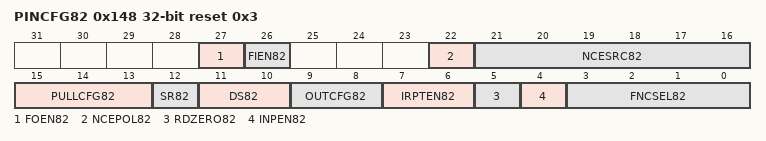
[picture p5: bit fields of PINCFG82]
0x148 PINCFG82 reset 0x3 — Controls the operation of GPIO pin 82.
  [27] FOEN82 — Force output enable active regardless of function selected. Otherwise the selected function will enable the output only when needed
  [26] FIEN82 — Force input enable active regardless of function selected. Otherwise the selected function will enable the input only when needed
  [22] NCEPOL82 — Polarity select for NCE for GPIO 82
    values as PINCFG62.NCEPOL62
  [21:16] NCESRC82 — IOMSTR/MSPI N Chip Select 82, DISP control signals DE, CSX, and CS. Polarity is determined by CE_POLARITY field
    values as PINCFG62.NCESRC62
  [15:13] PULLCFG82 — Pullup/Pulldown configuration for GPIO 82
    values as PINCFG62.PULLCFG62
  [12] SR82 — Configure the slew rate
  [11:10] DS82 — Drive strength selection for GPIO 82
    values as PINCFG62.DS62
  [9:8] OUTCFG82 — Pin IO mode selection for GPIO pin 82
    values as PINCFG62.OUTCFG62
  [7:6] IRPTEN82 — Interrupt enable for GPIO 82
    values as PINCFG62.IRPTEN62
  [5] RDZERO82 — Return 0 for read data on GPIO 82
  [4] INPEN82 — Input enable for GPIO 82
  [3:0] FNCSEL82 — Function select for GPIO pin 82
    0=MSPI2_8 (MSPI Master 2 Interface Signal); 1=32KHzXT (32kHZ from analog); 2=SDIF_DAT7 (SD/SDIO/MMC Data7 pin); 3=GPIO (General purpose I/O); 4=SWTRACE2 (Serial Wire Debug Trace Output 2); 5=DISP_PCLK (Display RGB Pixel Clock); 6=CT82 (Timer/Counter input or output; Selection of direction is done via CTIMER register settings.); 7=NCE82 (IOMSTR/MSPI N Chip Select. Polarity is determined by CE_POLARITY field); 8=OBSBUS2 (Observation bus bit 2); 11=FPIO (Fast PIO)
